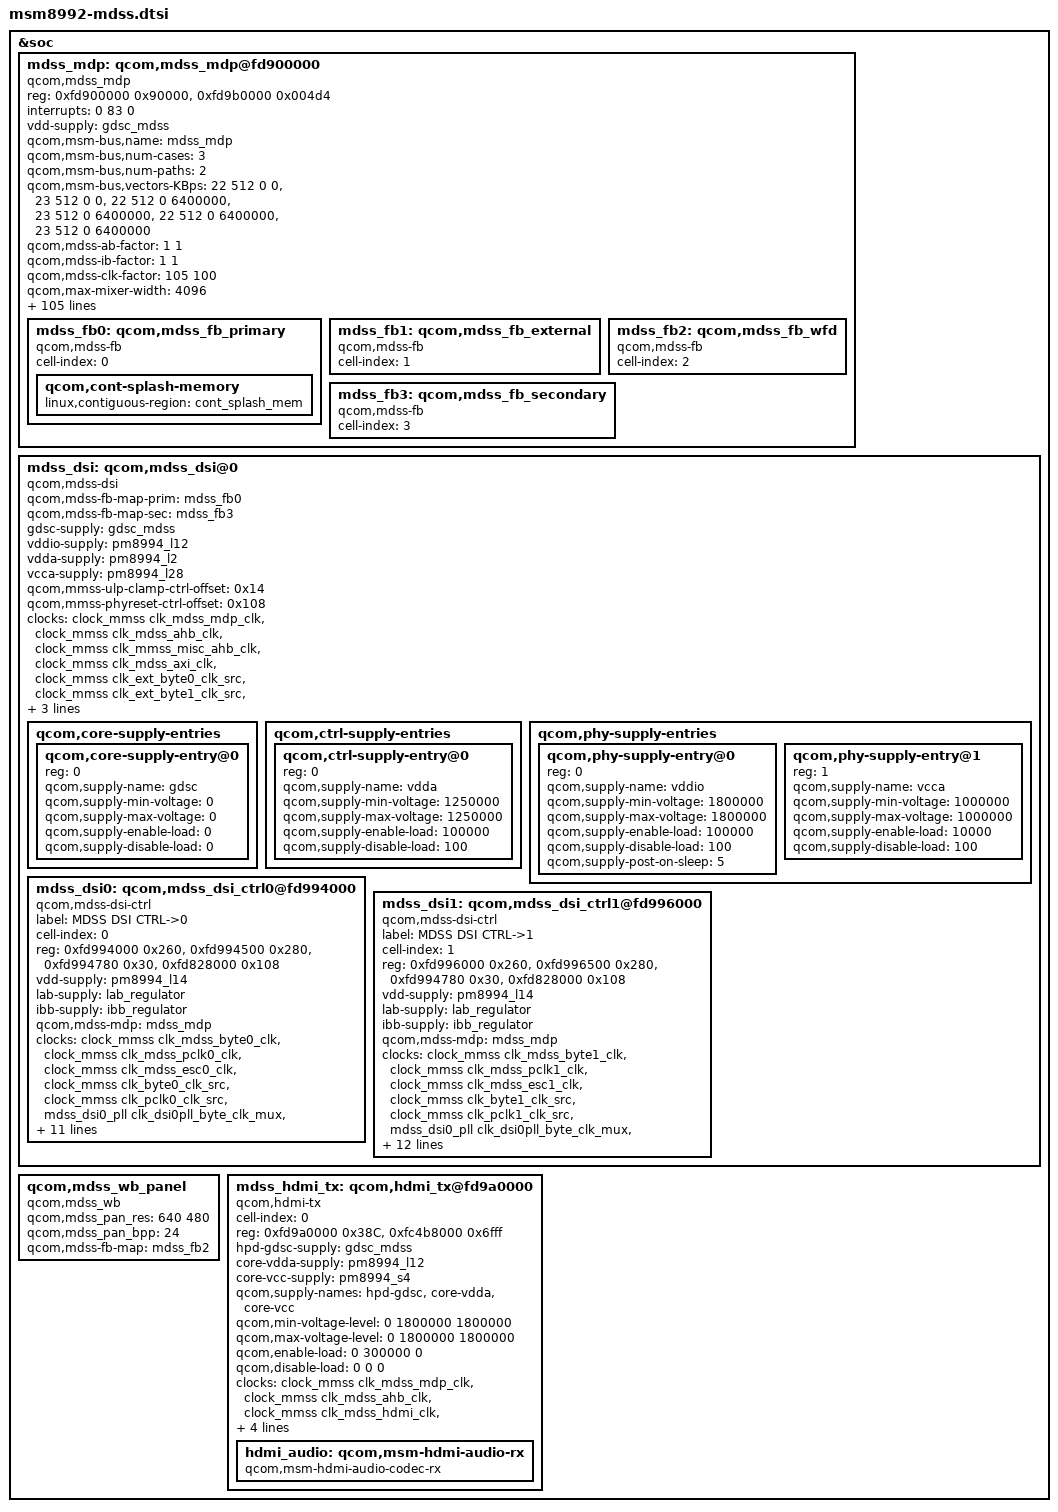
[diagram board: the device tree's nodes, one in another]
/* Copyright (c) 2014-2015 The Linux Foundation. All rights reserved.
 *
 * This program is free software; you can redistribute it and/or modify
 * it under the terms of the GNU General Public License version 2 and
 * only version 2 as published by the Free Software Foundation.
 *
 * This program is distributed in the hope that it will be useful,
 * but WITHOUT ANY WARRANTY; without even the implied warranty of
 * MERCHANTABILITY or FITNESS FOR A PARTICULAR PURPOSE.  See the
 * GNU General Public License for more details.
 */

&soc {
	mdss_mdp: qcom,mdss_mdp@fd900000 {
		compatible = "qcom,mdss_mdp";
		reg = <0xfd900000 0x90000>,
		      <0xfd9b0000 0x004d4>;
		reg-names = "mdp_phys", "vbif_phys";
		interrupts = <0 83 0>;
		vdd-supply = <&gdsc_mdss>;

		/* Bus Scale Settings */
		qcom,msm-bus,name = "mdss_mdp";
		qcom,msm-bus,num-cases = <3>;
		qcom,msm-bus,num-paths = <2>;
		qcom,msm-bus,vectors-KBps =
			<22 512 0 0>, <23 512 0 0>,
			<22 512 0 6400000>, <23 512 0 6400000>,
			<22 512 0 6400000>, <23 512 0 6400000>;

		/* Fudge factors */
		qcom,mdss-ab-factor = <1 1>;		/* No fudge factor */
		qcom,mdss-ib-factor = <1 1>;		/* No fudge factor */
		qcom,mdss-clk-factor = <105 100>;	/* 1.05 times */

		qcom,max-mixer-width = <4096>;
		qcom,max-pipe-width = <2048>;

		/* VBIF QoS remapper settings*/
		qcom,mdss-vbif-qos-rt-setting = <1 2 2 2>;
		qcom,mdss-vbif-qos-nrt-setting = <1 1 1 1>;

		qcom,mdss-mdp-reg-offset = <0x00001000>;
		qcom,max-bandwidth-low-kbps = <7000000>;
		qcom,max-bandwidth-high-kbps = <7000000>;
		qcom,max-bandwidth-per-pipe-kbps = <3100000>;
		qcom,max-clk-rate = <400000000>;
		qcom,mdss-dram-channels = <2>;
		qcom,mdss-default-ot-rd-limit = <24>;
		qcom,mdss-default-ot-wr-limit = <16>;
		qcom,mdss-pipe-vig-off = <0x00005000 0x00007000
					  0x00009000>;
		qcom,mdss-pipe-rgb-off = <0x00015000 0x00017000
					  0x00019000>;
		qcom,mdss-pipe-dma-off = <0x00025000 0x00027000>;
		qcom,mdss-pipe-cursor-off = <0x00035000>;
		qcom,mdss-ppb-off = <0x00000334>;
		qcom,mdss-slave-pingpong-off = <0x00073000>;

		qcom,mdss-pipe-vig-fetch-id = <1 4 7>;
		qcom,mdss-pipe-rgb-fetch-id = <16 17 18>;
		qcom,mdss-pipe-dma-fetch-id = <10 13>;

		qcom,mdss-pipe-vig-xin-id = <0 4 8>;
		qcom,mdss-pipe-rgb-xin-id = <1 5 9>;
		qcom,mdss-pipe-dma-xin-id = <2 10>;
		qcom,mdss-pipe-cursor-xin-id = <7>;

		qcom,mdss-has-panic-ctrl;
		qcom,mdss-pipe-vig-panic-ctrl-offsets = <0 1 2>;
		qcom,mdss-pipe-rgb-panic-ctrl-offsets = <4 5 6>;
		qcom,mdss-pipe-dma-panic-ctrl-offsets = <8 9>;

		qcom,mdss-pipe-rgb-fixed-mmb =	<5 0 1 6 7 8>,
						<5 2 3 9 10 11>,
						<5 4 5 12 13 14>;
		qcom,mdss-pipe-vig-fixed-mmb =	<1 15>,
						<1 16>,
						<1 17>;
		/* These Offsets are relative to "mdp_phys + mdp-reg-offset" address */
		qcom,mdss-pipe-vig-clk-ctrl-offsets = <0x2AC 0 0>,
						      <0x2B4 0 0>,
						      <0x2BC 0 0>;
		qcom,mdss-pipe-rgb-clk-ctrl-offsets = <0x2AC 4 8>,
						      <0x2B4 4 8>,
						      <0x2BC 4 8>;
		qcom,mdss-pipe-dma-clk-ctrl-offsets = <0x2AC 8 12>,
						      <0x2B4 8 12>;

		qcom,mdss-smp-data = <34 8192>;
		qcom,mdss-sspp-len = <0x00002000>;

		qcom,mdss-ctl-off = <0x00002000 0x00002200 0x00002400>;
		qcom,mdss-mixer-intf-off = <0x00045000 0x00046000>;
		qcom,mdss-mixer-wb-off = <0x000480000>;
		qcom,mdss-dspp-off = <0x00055000>;
		qcom,mdss-wb-off = <0x00065000 0x00065800 0x00066000>;
		qcom,mdss-intf-off = <0x0006B000 0x0006B800 0x0006C000 0x0006C800>;
		qcom,mdss-pingpong-off = <0x00071000 0x00071800>;
		qcom,mdss-ad-off = <0x0079000>;
		qcom,mdss-has-decimation;
		qcom,mdss-has-rotator-downscale;
		qcom,mdss-wfd-mode = "intf";
		qcom,mdss-has-source-split;
		qcom,mdss-has-dst-split;
		qcom,mdss-highest-bank-bit = <0x3>;
		qcom,mdss-has-bwc;

		clocks = <&clock_mmss clk_mdss_ahb_clk>,
			 <&clock_mmss clk_mdss_axi_clk>,
			 <&clock_mmss clk_mdp_clk_src>,
			 <&clock_mmss clk_mdss_mdp_clk>,
			 <&clock_mmss clk_mdss_vsync_clk>;
		clock-names = "iface_clk", "bus_clk", "core_clk_src",
				"core_clk", "vsync_clk";

		/* These Offsets are relative to "mdp_phys" address */
		qcom,mdp-settings = <0x0117c 0x0000FFFF>,
				    <0x01184 0xC000ff00>,
				    <0x011e0 0x000000a4>,
				    <0x011e4 0x00000000>,
				    <0x012ac 0xc0000ccc>,
				    <0x012b4 0xc0000ccc>,
				    <0x012bc 0x00cccccc>,
				    <0x012c4 0x000000cc>,
				    <0x013a8 0x0cccc0c0>,
				    <0x013b0 0xccccc0c0>,
				    <0x013b8 0xccccc0c0>,
				    <0x013d0 0x00ccc000>;

		qcom,regs-dump-mdp = <0x01000 0x01408>,
				     <0x02000 0x02064>,
				     <0x02200 0x02264>,
				     <0x02400 0x02464>,
				     <0x05000 0x05130>,
				     <0x05200 0x05230>,
				     <0x07000 0x07130>,
				     <0x07200 0x07230>,
				     <0x09000 0x09130>,
				     <0x09200 0x09230>,
				     <0x15000 0x15130>,
				     <0x15200 0x15230>,
				     <0x17000 0x17130>,
				     <0x17200 0x17230>,
				     <0x19000 0x19130>,
				     <0x19200 0x19230>,
				     <0x25000 0x2512C>,
				     <0x27000 0x2712C>,
				     <0x45000 0x4538c>,
				     <0x46000 0x4638c>,
				     <0x48000 0x4838c>,
				     <0x55000 0x5522c>,
				     <0x65000 0x652b4>,
				     <0x65800 0x65ab4>,
				     <0x66000 0x662b4>,
				     <0x6b800 0x6ba54>,
				     <0x6c000 0x6c254>,
				     <0x6c800 0x6ca54>,
				     <0x71000 0x710d0>,
				     <0x71800 0x718d0>,
				     <0x73000 0x730d0>;

		qcom,regs-dump-names-mdp = "MDP",
			"CTL_0",    "CTL_1", "CTL_2",
			"VIG0_SSPP", "VIG0",  "VIG1_SSPP", "VIG1",
			"VIG2_SSPP", "VIG2",
			"RGB0_SSPP", "RGB0",  "RGB1_SSPP", "RGB1",
			"RGB2_SSPP", "RGB2",
			"DMA0_SSPP", "DMA1_SSPP",
			"LAYER_0", "LAYER_1", "LAYER_3",
			"DSPP_0",
			"WB_0",    "WB_1",    "WB_2",
			"INTF_1",  "INTF_2", "INTF_3",
			"PP_0",    "PP_1",   "PP_4";

		/* buffer parameters to calculate prefill bandwidth */
		qcom,mdss-prefill-outstanding-buffer-bytes = <1024>;
		qcom,mdss-prefill-y-buffer-bytes = <4096>;
		qcom,mdss-prefill-scaler-buffer-lines-bilinear = <2>;
		qcom,mdss-prefill-scaler-buffer-lines-caf = <4>;
		qcom,mdss-prefill-post-scaler-buffer-pixels = <2048>;
		qcom,mdss-prefill-pingpong-buffer-pixels = <5120>;
		qcom,mdss-prefill-fbc-lines = <2>;

		mdss_fb0: qcom,mdss_fb_primary {
			cell-index = <0>;
			compatible = "qcom,mdss-fb";
			qcom,cont-splash-memory {
				linux,contiguous-region = <&cont_splash_mem>;
			};
		};

		mdss_fb1: qcom,mdss_fb_external {
			cell-index = <1>;
			compatible = "qcom,mdss-fb";
		};

		mdss_fb2: qcom,mdss_fb_wfd {
			cell-index = <2>;
			compatible = "qcom,mdss-fb";
		};

		mdss_fb3: qcom,mdss_fb_secondary {
			cell-index = <3>;
			compatible = "qcom,mdss-fb";
		};
	};

	mdss_dsi: qcom,mdss_dsi@0 {
		compatible = "qcom,mdss-dsi";
		#address-cells = <1>;
		#size-cells = <1>;
		qcom,mdss-fb-map-prim = <&mdss_fb0>;
		qcom,mdss-fb-map-sec = <&mdss_fb3>;
		gdsc-supply = <&gdsc_mdss>;
		vddio-supply = <&pm8994_l12>;
		vdda-supply = <&pm8994_l2>;
		vcca-supply = <&pm8994_l28>;
		ranges = <0xfd994000 0xfd994000 0x260
			0xfd994500 0xfd994500 0x280
			0xfd994780 0xfd994780 0x30
			0xfd828000 0xfd828000 0x108
			0xfd996000 0xfd996000 0x260
			0xfd996500 0xfd996500 0x280
			0xfd994780 0xfd994780 0x30
			0xfd828000 0xfd828000 0x108>;

		qcom,mmss-ulp-clamp-ctrl-offset = <0x14>;
		qcom,mmss-phyreset-ctrl-offset = <0x108>;

		clocks = <&clock_mmss clk_mdss_mdp_clk>,
			<&clock_mmss clk_mdss_ahb_clk>,
			<&clock_mmss clk_mmss_misc_ahb_clk>,
			<&clock_mmss clk_mdss_axi_clk>,
			<&clock_mmss clk_ext_byte0_clk_src>,
			<&clock_mmss clk_ext_byte1_clk_src>,
			<&clock_mmss clk_ext_pclk0_clk_src>,
			<&clock_mmss clk_ext_pclk1_clk_src>;
		clock-names = "mdp_core_clk", "iface_clk",
			"core_mmss_clk", "bus_clk",
			"ext_byte0_clk", "ext_byte1_clk",
			"ext_pixel0_clk", "ext_pixel1_clk";

		qcom,timing-db-mode;

		qcom,core-supply-entries {
			#address-cells = <1>;
			#size-cells = <0>;

			qcom,core-supply-entry@0 {
				reg = <0>;
				qcom,supply-name = "gdsc";
				qcom,supply-min-voltage = <0>;
				qcom,supply-max-voltage = <0>;
				qcom,supply-enable-load = <0>;
				qcom,supply-disable-load = <0>;
			};
		};

		qcom,ctrl-supply-entries {
			#address-cells = <1>;
			#size-cells = <0>;

			qcom,ctrl-supply-entry@0 {
				reg = <0>;
				qcom,supply-name = "vdda";
				qcom,supply-min-voltage = <1250000>;
				qcom,supply-max-voltage = <1250000>;
				qcom,supply-enable-load = <100000>;
				qcom,supply-disable-load = <100>;
			};
		};

		qcom,phy-supply-entries {
			#address-cells = <1>;
			#size-cells = <0>;

			qcom,phy-supply-entry@0 {
				reg = <0>;
				qcom,supply-name = "vddio";
				qcom,supply-min-voltage = <1800000>;
				qcom,supply-max-voltage = <1800000>;
				qcom,supply-enable-load = <100000>;
				qcom,supply-disable-load = <100>;
				qcom,supply-post-on-sleep = <5>;
			};

			qcom,phy-supply-entry@1 {
				reg = <1>;
				qcom,supply-name = "vcca";
				qcom,supply-min-voltage = <1000000>;
				qcom,supply-max-voltage = <1000000>;
				qcom,supply-enable-load = <10000>;
				qcom,supply-disable-load = <100>;
			};
		};

		mdss_dsi0: qcom,mdss_dsi_ctrl0@fd994000 {
			compatible = "qcom,mdss-dsi-ctrl";
			label = "MDSS DSI CTRL->0";
			cell-index = <0>;
			reg = 	<0xfd994000 0x260>,
				<0xfd994500 0x280>,
				<0xfd994780 0x30>,
				<0xfd828000 0x108>;
			reg-names = "dsi_ctrl", "dsi_phy",
				"dsi_phy_regulator", "mmss_misc_phys";

			vdd-supply = <&pm8994_l14>;
			lab-supply = <&lab_regulator>;
			ibb-supply = <&ibb_regulator>;
			qcom,mdss-mdp = <&mdss_mdp>;

			clocks = <&clock_mmss clk_mdss_byte0_clk>,
				<&clock_mmss clk_mdss_pclk0_clk>,
				<&clock_mmss clk_mdss_esc0_clk>,
				<&clock_mmss clk_byte0_clk_src>,
				<&clock_mmss clk_pclk0_clk_src>,
				<&mdss_dsi0_pll clk_dsi0pll_byte_clk_mux>,
				<&mdss_dsi0_pll clk_dsi0pll_pixel_clk_mux>,
				<&mdss_dsi0_pll clk_dsi0pll_byte_clk_src>,
				<&mdss_dsi0_pll clk_dsi0pll_pixel_clk_src>,
				<&mdss_dsi0_pll clk_dsi0pll_shadow_byte_clk_src>,
				<&mdss_dsi0_pll clk_dsi0pll_shadow_pixel_clk_src>;
			clock-names = "byte_clk", "pixel_clk", "core_clk",
				"byte_clk_rcg", "pixel_clk_rcg",
				"pll_byte_clk_mux", "pll_pixel_clk_mux",
				"pll_byte_clk_src", "pll_pixel_clk_src",
				"pll_shadow_byte_clk_src", "pll_shadow_pixel_clk_src";

			qcom,platform-strength-ctrl = [77 06];
			qcom,platform-bist-ctrl = [00 00 b1 ff 00 00];
			qcom,platform-regulator-settings = [03 03 03 00 20 07 01];
			qcom,platform-lane-config = [
				02 a0 00 00 20 00 00 01 46
				02 a0 00 00 40 00 00 01 46
				02 a0 00 40 20 00 00 01 46
				02 a0 00 40 00 00 00 01 46
				00 a0 00 80 00 00 00 01 46];
		};

		mdss_dsi1: qcom,mdss_dsi_ctrl1@fd996000 {
			compatible = "qcom,mdss-dsi-ctrl";
			label = "MDSS DSI CTRL->1";
			cell-index = <1>;
			reg = 	<0xfd996000 0x260>,
				<0xfd996500 0x280>,
				<0xfd994780 0x30>,
				<0xfd828000 0x108>;
			reg-names = "dsi_ctrl", "dsi_phy",
				"dsi_phy_regulator", "mmss_misc_phys";

			vdd-supply = <&pm8994_l14>;
			lab-supply = <&lab_regulator>;
			ibb-supply = <&ibb_regulator>;
			qcom,mdss-mdp = <&mdss_mdp>;

			clocks = <&clock_mmss clk_mdss_byte1_clk>,
				<&clock_mmss clk_mdss_pclk1_clk>,
				<&clock_mmss clk_mdss_esc1_clk>,
				<&clock_mmss clk_byte1_clk_src>,
				<&clock_mmss clk_pclk1_clk_src>,
				<&mdss_dsi0_pll clk_dsi0pll_byte_clk_mux>,
				<&mdss_dsi0_pll clk_dsi0pll_pixel_clk_mux>,
				<&mdss_dsi0_pll clk_dsi0pll_byte_clk_src>,
				<&mdss_dsi0_pll clk_dsi0pll_pixel_clk_src>,
				<&mdss_dsi0_pll clk_dsi0pll_shadow_byte_clk_src>,
				<&mdss_dsi0_pll clk_dsi0pll_shadow_pixel_clk_src>,
				<&mdss_dsi1_pll clk_dsi1pll_vco_dummy_clk>;
			clock-names = "byte_clk", "pixel_clk", "core_clk",
				"byte_clk_rcg", "pixel_clk_rcg",
				"pll_byte_clk_mux", "pll_pixel_clk_mux",
				"pll_byte_clk_src", "pll_pixel_clk_src",
				"pll_shadow_byte_clk_src", "pll_shadow_pixel_clk_src",
				"pll_vco_dummy_clk";

			qcom,platform-strength-ctrl = [77 06];
			qcom,platform-bist-ctrl = [00 00 b1 ff 00 00];
			qcom,platform-regulator-settings = [03 03 03 00 20 07 01];
			qcom,platform-lane-config = [
				02 a0 00 00 20 00 00 01 46
				02 a0 00 00 40 00 00 01 46
				02 a0 00 40 20 00 00 01 46
				02 a0 00 40 00 00 00 01 46
				00 a0 00 80 00 00 00 01 46];
		};
	};

	qcom,mdss_wb_panel {
		compatible = "qcom,mdss_wb";
		qcom,mdss_pan_res = <640 480>;
		qcom,mdss_pan_bpp = <24>;
		qcom,mdss-fb-map = <&mdss_fb2>;
	};

	mdss_hdmi_tx: qcom,hdmi_tx@fd9a0000{
		status = "ok";
		cell-index = <0>;
		compatible = "qcom,hdmi-tx";

		reg = <0xfd9a0000 0x38C>, <0xfc4b8000 0x6fff>;
		reg-names = "core_physical", "qfprom_physical";

		hpd-gdsc-supply = <&gdsc_mdss>;
		core-vdda-supply = <&pm8994_l12>;
		core-vcc-supply = <&pm8994_s4>;

		qcom,supply-names = "hpd-gdsc", "core-vdda", "core-vcc";
		qcom,min-voltage-level = <0 1800000 1800000>;
		qcom,max-voltage-level = <0 1800000 1800000>;
		qcom,enable-load = <0 300000 0>;
		qcom,disable-load = <0 0 0>;

		clocks = <&clock_mmss clk_mdss_mdp_clk>,
				<&clock_mmss clk_mdss_ahb_clk>,
				<&clock_mmss clk_mdss_hdmi_clk>,
				<&clock_mmss clk_mdss_hdmi_ahb_clk>,
				<&clock_mmss clk_mdss_extpclk_clk>;
		clock-names = "mdp_core_clk", "iface_clk",
				"core_clk", "alt_iface_clk", "extp_clk";

		qcom,hdmi-tx-hpd = <&pm8994_mpps 4 0>;
		qcom,mdss-fb-map = <&mdss_fb1>;
		hdmi_audio: qcom,msm-hdmi-audio-rx {
			compatible = "qcom,msm-hdmi-audio-codec-rx";
		};
	};
};

#include "msm8992-mdss-panels.dtsi"
